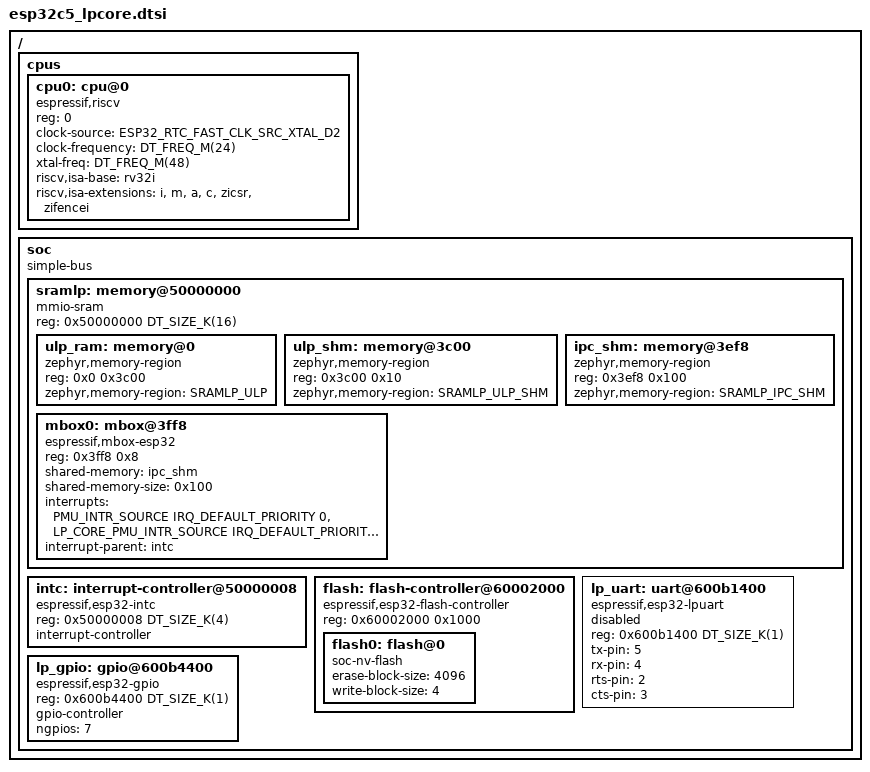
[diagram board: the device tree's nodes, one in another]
/*
 * Copyright (c) 2026 Espressif Systems (Shanghai) Co., Ltd.
 *
 * SPDX-License-Identifier: Apache-2.0
 */
#include <mem.h>
#include <freq.h>
#include <zephyr/dt-bindings/gpio/gpio.h>
#include <zephyr/dt-bindings/interrupt-controller/esp-esp32c5-intmux.h>
#include <zephyr/dt-bindings/clock/esp32c5_clock.h>
#include <zephyr/dt-bindings/pinctrl/esp32c5-pinctrl.h>

/ {
	#address-cells = <1>;
	#size-cells = <1>;

	cpus {
		#address-cells = <1>;
		#size-cells = <0>;

		cpu0: cpu@0 {
			compatible = "espressif,riscv", "riscv";
			reg = <0>;
			device_type = "cpu";
			clock-source = <ESP32_RTC_FAST_CLK_SRC_XTAL_D2>;
			clock-frequency = <DT_FREQ_M(24)>;
			xtal-freq = <DT_FREQ_M(48)>;
			riscv,isa-base = "rv32i";
			riscv,isa-extensions = "i", "m", "a", "c", "zicsr", "zifencei";
		};
	};

	soc {
		compatible = "simple-bus";
		ranges;
		#address-cells = <1>;
		#size-cells = <1>;

		sramlp: memory@50000000 {
			compatible = "mmio-sram";
			reg = <0x50000000 DT_SIZE_K(16)>;
			ranges = <0x0 0x50000000 DT_SIZE_K(16)>;
			#address-cells = <1>;
			#size-cells = <1>;

			ulp_ram: memory@0 {
				compatible = "zephyr,memory-region", "mmio-sram";
				reg = <0x0 0x3c00>;
				zephyr,memory-region = "SRAMLP_ULP";
			};

			ulp_shm: memory@3c00 {
				compatible = "zephyr,memory-region", "mmio-sram";
				reg = <0x3c00 0x10>;
				zephyr,memory-region = "SRAMLP_ULP_SHM";
			};

			ipc_shm: memory@3ef8 {
				compatible = "zephyr,memory-region", "mmio-sram";
				reg = <0x3ef8 0x100>;
				zephyr,memory-region = "SRAMLP_IPC_SHM";
			};

			mbox0: mbox@3ff8 {
				compatible = "espressif,mbox-esp32";
				reg = <0x3ff8 0x8>;
				shared-memory = <&ipc_shm>;
				shared-memory-size = <0x100>;
				interrupts = <PMU_INTR_SOURCE IRQ_DEFAULT_PRIORITY 0>,
					     <LP_CORE_PMU_INTR_SOURCE IRQ_DEFAULT_PRIORITY 0>;
				interrupt-parent = <&intc>;
				#mbox-cells = <1>;
				status = "okay";
			};
		};

		intc: interrupt-controller@50000008 {
			compatible = "espressif,esp32-intc";
			reg = <0x50000008 DT_SIZE_K(4)>;
			#address-cells = <0>;
			#interrupt-cells = <3>;
			interrupt-controller;
			status = "okay";
		};

		flash: flash-controller@60002000 {
			compatible = "espressif,esp32-flash-controller";
			reg = <0x60002000 0x1000>;
			ranges;
			#address-cells = <1>;
			#size-cells = <1>;

			flash0: flash@0 {
				compatible = "soc-nv-flash";
				erase-block-size = <4096>;
				write-block-size = <4>;
				#address-cells = <1>;
				#size-cells = <1>;
				/* reg and ranges are specified in SOC/SIP dtsi */
			};
		};

		lp_uart: uart@600b1400 {
			compatible = "espressif,esp32-lpuart";
			reg = <0x600b1400 DT_SIZE_K(1)>;
			tx-pin = <5>;
			rx-pin = <4>;
			rts-pin = <2>;
			cts-pin = <3>;
			status = "disabled";
		};

		lp_gpio: gpio@600b4400 {
			compatible = "espressif,esp32-gpio";
			reg = <0x600b4400 DT_SIZE_K(1)>;
			gpio-controller;
			#gpio-cells = <2>;
			ngpios = <7>;
		};
	};
};
